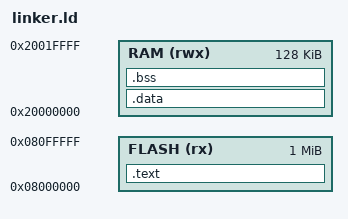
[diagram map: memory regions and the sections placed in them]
ENTRY(Reset_Handler)

/* STM32F407VG memory map */
MEMORY
{
  FLASH (rx)  : ORIGIN = 0x08000000, LENGTH = 1024K
  RAM   (rwx) : ORIGIN = 0x20000000, LENGTH = 128K
}

/* Stack top */
_estack = ORIGIN(RAM) + LENGTH(RAM);

SECTIONS
{
  /* Vector table + code */
  .text :
  {
    KEEP(*(.isr_vector))
    *(.text*)
    *(.rodata*)
    _etext = .;
  } > FLASH

  /* Initialized data */
  .data : AT (_etext)
  {
    _sdata = .;
    *(.data*)
    _edata = .;
  } > RAM

  _sidata = LOADADDR(.data);

  /* Zero-initialized data */
  .bss :
  {
    _sbss = .;
    *(.bss*)
    *(COMMON)
    _ebss = .;
  } > RAM
}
